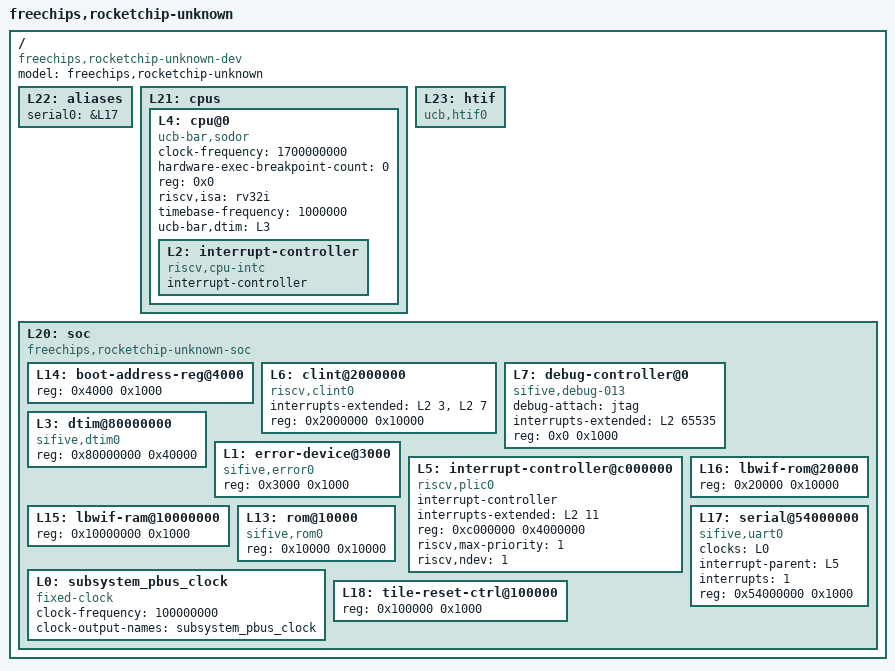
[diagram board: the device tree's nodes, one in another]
/dts-v1/;

/ {
	#address-cells = <1>;
	#size-cells = <1>;
	compatible = "freechips,rocketchip-unknown-dev";
	model = "freechips,rocketchip-unknown";
	L22: aliases {
		serial0 = &L17;
	};
	L21: cpus {
		#address-cells = <1>;
		#size-cells = <0>;
		L4: cpu@0 {
			clock-frequency = <1700000000>;
			compatible = "ucb-bar,sodor", "riscv";
			device_type = "cpu";
			hardware-exec-breakpoint-count = <0>;
			reg = <0x0>;
			riscv,isa = "rv32i";
			status = "okay";
			timebase-frequency = <1000000>;
			ucb-bar,dtim = <&L3>;
			L2: interrupt-controller {
				#interrupt-cells = <1>;
				compatible = "riscv,cpu-intc";
				interrupt-controller;
			};
		};
	};
	L23: htif {
		compatible = "ucb,htif0";
	};
	L20: soc {
		#address-cells = <1>;
		#size-cells = <1>;
		compatible = "freechips,rocketchip-unknown-soc", "simple-bus";
		ranges;
		L14: boot-address-reg@4000 {
			reg = <0x4000 0x1000>;
			reg-names = "control";
		};
		L6: clint@2000000 {
			compatible = "riscv,clint0";
			interrupts-extended = <&L2 3 &L2 7>;
			reg = <0x2000000 0x10000>;
			reg-names = "control";
		};
		L7: debug-controller@0 {
			compatible = "sifive,debug-013", "riscv,debug-013";
			debug-attach = "jtag";
			interrupts-extended = <&L2 65535>;
			reg = <0x0 0x1000>;
			reg-names = "control";
		};
		L3: dtim@80000000 {
			compatible = "sifive,dtim0";
			reg = <0x80000000 0x40000>;
			reg-names = "mem";
		};
		L1: error-device@3000 {
			compatible = "sifive,error0";
			reg = <0x3000 0x1000>;
		};
		L5: interrupt-controller@c000000 {
			#interrupt-cells = <1>;
			compatible = "riscv,plic0";
			interrupt-controller;
			interrupts-extended = <&L2 11>;
			reg = <0xc000000 0x4000000>;
			reg-names = "control";
			riscv,max-priority = <1>;
			riscv,ndev = <1>;
		};
		L15: lbwif-ram@10000000 {
			reg = <0x10000000 0x1000>;
		};
		L16: lbwif-rom@20000 {
			reg = <0x20000 0x10000>;
		};
		L13: rom@10000 {
			compatible = "sifive,rom0";
			reg = <0x10000 0x10000>;
			reg-names = "mem";
		};
		L17: serial@54000000 {
			clocks = <&L0>;
			compatible = "sifive,uart0";
			interrupt-parent = <&L5>;
			interrupts = <1>;
			reg = <0x54000000 0x1000>;
			reg-names = "control";
		};
		L0: subsystem_pbus_clock {
			#clock-cells = <0>;
			clock-frequency = <100000000>;
			clock-output-names = "subsystem_pbus_clock";
			compatible = "fixed-clock";
		};
		L18: tile-reset-ctrl@100000 {
			reg = <0x100000 0x1000>;
			reg-names = "control";
		};
	};
};
